# PIC32MK1024MCF064 device description
Architecture: MIPS; Family: PIC32MK; Series: PIC32MK
Registers are 32-bit, read-write, no defined reset value unless marked. A register's access mark holds for its fields unless they carry their own. Offsets are from the block's base; [hi:lo] are bit positions; 'fields as' and 'values as' point back to an identical list; <NAME> marks a mode.

## QEI
Instances: QEI 0x1f82b200 in periph_pb2_std
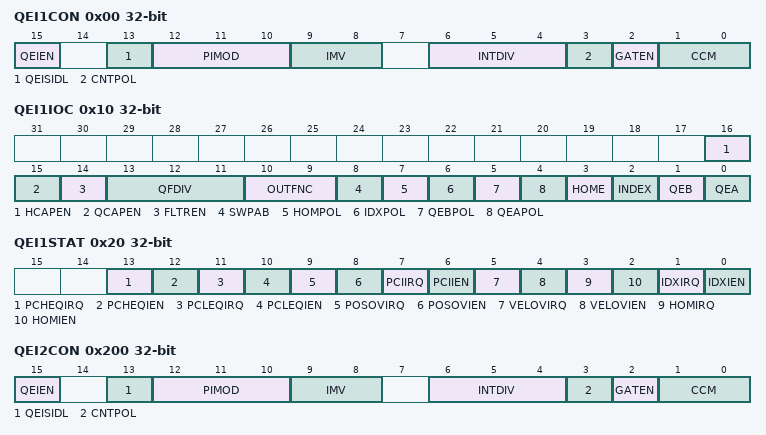
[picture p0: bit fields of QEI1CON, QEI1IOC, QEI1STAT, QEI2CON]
0x00 QEI1CON — QEIx Control Register
  [15] QEIEN — Quadrature Encoder Interface Module Counter Enable bit
    1=Module counters are enabled; 0=Module counters are disabled
  [13] QEISIDL — Stop in Idle Mode bit
    1=Discontinue module operation when device enters Idle mode; 0=Continue module operation in Idle mode
  [12:10] PIMOD — Position Counter Initialization Mode Select bits
    7=Modulo Count mode for position counter and every index event resets the position counter; 6=Modulo Count mode for position counter; 5=Resets the position counter when the position counter equals QEIxICCH register; 4=Second index event after home event initializes position counter with contents of QEIxICCHregister; 3=First index event after home event initializes position counter with contents of QEIxICCH register; 2=Next index input event initializes the position counter with contents of QEIxICCH register; 1=Every Index input event resets the position counter; 0=Index input event does not affect position counter
  [9:8] IMV — Index Match Value bits
    3=Index match occurs when QEB is 1 and QEA is 1; 2=Index match occurs when QEB is 1 and QEA is 0; 1=Index match occurs when QEB is 0 and QEA is 1; 0=Index match occurs when QEB is 0 and QEA is 0
  [6:4] INTDIV — Timer Input Clock Prescale Select bits
    7=1:128 prescale value; 6=1:64 prescale value; 5=1:32 prescale value; 4=1:16 prescale value; 3=1:8 prescale value; 2=1:4 prescale value; 1=1:2 prescale value; 0=1:1 prescale value
  [3] CNTPOL — Position and Index Counter/Timer Direction Select bit
    1=Counter direction is negative unless modified by external Up/Down signal; 0=Counter direction is positive unless modified by external Up/Down signal
  [2] GATEN — External Count Gate Enable bit
    1=External gate signal controls position counter operation; 0=External gate signal does not affect position counter/timer operation
  [1:0] CCM — Counter Control Mode Selection bits
    3=Internal Timer Mode. QEB High is Timer Run, QEB Low is Timer Stop; 2=QEA is the external clock input. QEB High is Clock Run, QEB Low is Clock Stop; 1=QEA is the external clock input. QEB High is Count Up, QEB Low is Count Down; 0=Quadrature Encoder Interface Count mode (x4 mode)
0x10 QEI1IOC — QEIx I/O Control Register
  [16] HCAPEN — Position Counter Input Capture by Home Event Enable bit
    1=HOMEx input event (positive edge) triggers a position capture event; 0=HOMEx input event (positive edge) does not trigger a position capture event
  [15] QCAPEN — Position Counter Input Capture Enable bit
    1=Positive edge detect of Home input triggers position capture function; 0=Home input event (positive edge) does not trigger a capture even
  [14] FLTREN — QEA/QEB/INDX/HOMEx Digital Filter Enable bit
    1=Input Pin Digital filter is enabled; 0=Input Pin Digital filter is disabled (bypassed)
  [13:11] QFDIV — QEA/QEB/INDX/HOMEx Digital Input Filter Clock Divide Select bits
    7=1:128 clock divide; 6=1:64 clock divide; 5=1:32 clock divide; 4=1:16 clock divide; 3=1:8 clock divide; 2=1:4 clock divide; 1=1:2 clock divide; 0=1:1 clock divide
  [10:9] OUTFNC — QEI Module Output Function Mode Select bits
    3=The CNTCMPx pin goes high when POSxCNT QEIxCMPL or POSxCNT QEIxICCH; 2=The CNTCMPx pin goes high when POSxCNT QEIxCMPL; 1=The CNTCMPx pin goes high when POSxCNT QEIxICCH; 0=Output is disabled
  [8] SWPAB — Swap QEA and QEB Inputs bit
    1=QEAx and QEBx are swapped prior to quadrature decoder logic; 0=QEAx and QEBx are not swapped
  [7] HOMPOL — HOMEx Input Polarity Select bit
    1=Input is inverted; 0=Input is not inverted
  [6] IDXPOL — INDXx Input Polarity Select bit
    1=Input is inverted; 0=Input is not inverted
  [5] QEBPOL — QEBx Input Polarity Select bit
    1=Input is inverted; 0=Input is not inverted
  [4] QEAPOL — QEAx Input Polarity Select bit
    1=Input is inverted; 0=Input is not inverted
  [3] HOME — Status of HOMEx Input Pin after Polarity Control bit
    1=(if HOMPOL bit is set to 0) Pin is at logic 1 / (if HOMPOL bit is set to 1) Pin is at logic 0; 0=(if HOMPOL bit is set to 0) Pin is at logic 0 / (if HOMPOL bit is set to 1) Pin is at logic 1
  [2] INDEX — Status of INDXx Input Pin after Polarity Control bit
    1=(if IDXPOL bit is set to 0) Pin is at logic 1 / (if IDXPOL bit is set to 1) Pin is at logic 0; 0=(if IDXPOL bit is set to 0) Pin is at logic 0 / (if IDXPOL bit is set to 1) Pin is at logic 1
  [1] QEB — Status of QEBx Input Pin after Polarity Control and SWPAB Pin Swapping bit
    1=see datasheet; 0=see datasheet
  [0] QEA — Status of QEAx Input Pin after Polarity Control and SWPAB Pin Swapping bit
    1=see datasheet; 0=see datasheet
0x20 QEI1STAT — QEIx Status Register
  [13] PCHEQIRQ — Position Counter Greater Than or Equal Compare Status bit
    1=POSxCNT; 0=POSxCNT < QEIxICCH
  [12] PCHEQIEN — Position Counter Greater Than or Equal Compare Interrupt Enable bit
    1=Interrupt is enabled; 0=Interrupt is disabled
  [11] PCLEQIRQ — Position Counter Less Than or Equal Compare Status bit
    1=POSxCNT; 0=POSxCNT > QEIxCMPL
  [10] PCLEQIEN — Position Counter Less Than or Equal Compare Interrupt Enable bit
    1=Interrupt is enabled; 0=Interrupt is disabled
  [9] POSOVIRQ — Position Counter Overflow Status bit
    1=Overflow has occurred; 0=No overflow has occurred
  [8] POSOVIEN — Position Counter Overflow Interrupt Enable bit
    1=Interrupt is enabled; 0=Interrupt is disabled
  [7] PCIIRQ — Position Counter Initialization Process Complete Status bit
    1=POSxCNT was reinitialized; 0=POSxCNT was not reinitialized
  [6] PCIIEN — Position Counter Initialization Process Complete Interrupt Enable bit
    1=Interrupt is enabled; 0=Interrupt is disabled
  [5] VELOVIRQ — Velocity Counter Overflow Status bit
    1=Overflow has occurred; 0=No overflow has not occurred
  [4] VELOVIEN — Velocity Counter Overflow Interrupt Enable bit
    1=Interrupt is enabled; 0=Interrupt is disabled
  [3] HOMIRQ — Status Flag for Home Event Status bit
    1=Home event has occurred; 0=No Home event has occurred
  [2] HOMIEN — Home Input Event Interrupt Enable bit
    1=Interrupt is enabled; 0=Interrupt is disabled
  [1] IDXIRQ — Status Flag for Index Event Status bit
    1=Index event has occurred; 0=No Index event has occurred
  [0] IDXIEN — Index Input Event Interrupt Enable bit
    1=Interrupt is enabled; 0=Interrupt is disabled
0x30 POS1CNT — Position Counter Register
  [31:0] POSCNT
0x40 POS1HLD
  [31:0] POSHLD
0x50 VEL1CNT — Velocity Counter Register
  [31:0] VELCNT
0x60 VEL1HLD — Velocity Hold Register
  [31:0] VELHLD
0x70 INT1TMR — Interval Timer Register
  [31:0] INTTMR
0x80 INT1HLD — Interval Timer Hold Register
  [31:0] INTHLD
0x90 INDX1CNT
  [31:0] INDXCNT
0xA0 INDX1HLD
  [31:0] INDXHLD
0xB0 QEI1ICC — QEIx Initialize/Capture/Compare Register
  [31:0] QEIICC
0xC0 QEI1CMPL — Capture Low Register
  [31:0] QEICMPL
0x200 QEI2CON — QEIx Control Register
  fields as QEI1CON
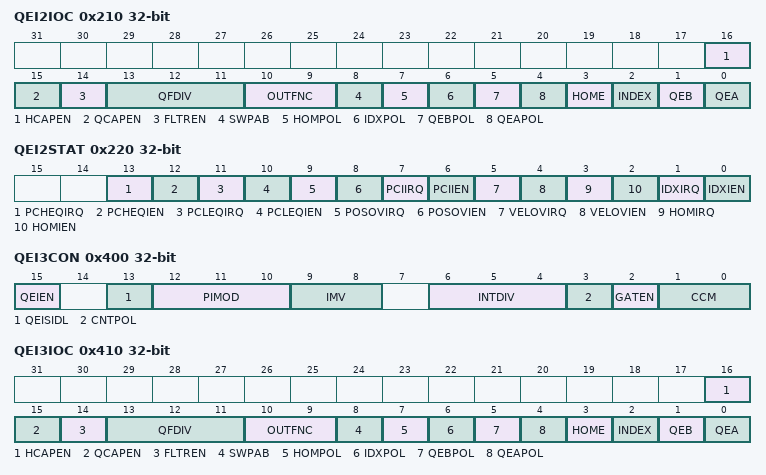
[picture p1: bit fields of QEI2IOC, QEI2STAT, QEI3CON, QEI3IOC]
0x210 QEI2IOC — QEIx I/O Control Register
  fields as QEI1IOC
0x220 QEI2STAT — QEIx Status Register
  fields as QEI1STAT
0x230 POS2CNT — Position Counter Register
  [31:0] POSCNT
0x240 POS2HLD
  [31:0] POSHLD
0x250 VEL2CNT — Velocity Counter Register
  [31:0] VELCNT
0x260 VEL2HLD — Velocity Hold Register
  [31:0] VELHLD
0x270 INT2TMR — Interval Timer Register
  [31:0] INTTMR
0x280 INT2HLD — Interval Timer Hold Register
  [31:0] INTHLD
0x290 INDX2CNT
  [31:0] INDXCNT
0x2A0 INDX2HLD
  [31:0] INDXHLD
0x2B0 QEI2ICC — QEIx Initialize/Capture/Compare Register
  [31:0] QEIICC
0x2C0 QEI2CMPL — Capture Low Register
  [31:0] QEICMPL
0x400 QEI3CON — QEIx Control Register
  fields as QEI1CON
0x410 QEI3IOC — QEIx I/O Control Register
  fields as QEI1IOC
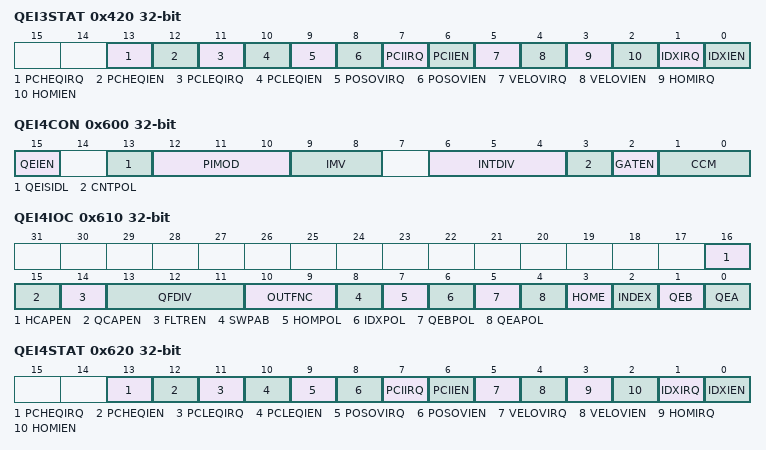
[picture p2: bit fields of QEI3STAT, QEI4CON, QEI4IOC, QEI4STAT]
0x420 QEI3STAT — QEIx Status Register
  fields as QEI1STAT
0x430 POS3CNT — Position Counter Register
  [31:0] POSCNT
0x440 POS3HLD
  [31:0] POSHLD
0x450 VEL3CNT — Velocity Counter Register
  [31:0] VELCNT
0x460 VEL3HLD — Velocity Hold Register
  [31:0] VELHLD
0x470 INT3TMR — Interval Timer Register
  [31:0] INTTMR
0x480 INT3HLD — Interval Timer Hold Register
  [31:0] INTHLD
0x490 INDX3CNT
  [31:0] INDXCNT
0x4A0 INDX3HLD
  [31:0] INDXHLD
0x4B0 QEI3ICC — QEIx Initialize/Capture/Compare Register
  [31:0] QEIICC
0x4C0 QEI3CMPL — Capture Low Register
  [31:0] QEICMPL
0x600 QEI4CON — QEIx Control Register
  fields as QEI1CON
0x610 QEI4IOC — QEIx I/O Control Register
  fields as QEI1IOC
0x620 QEI4STAT — QEIx Status Register
  fields as QEI1STAT
0x630 POS4CNT — Position Counter Register
  [31:0] POSCNT
0x640 POS4HLD
  [31:0] POSHLD
0x650 VEL4CNT — Velocity Counter Register
  [31:0] VELCNT
0x660 VEL4HLD — Velocity Hold Register
  [31:0] VELHLD
0x670 INT4TMR — Interval Timer Register
  [31:0] INTTMR
0x680 INT4HLD — Interval Timer Hold Register
  [31:0] INTHLD
0x690 INDX4CNT
  [31:0] INDXCNT
0x6A0 INDX4HLD
  [31:0] INDXHLD
0x6B0 QEI4ICC — QEIx Initialize/Capture/Compare Register
  [31:0] QEIICC
0x6C0 QEI4CMPL — Capture Low Register
  [31:0] QEICMPL
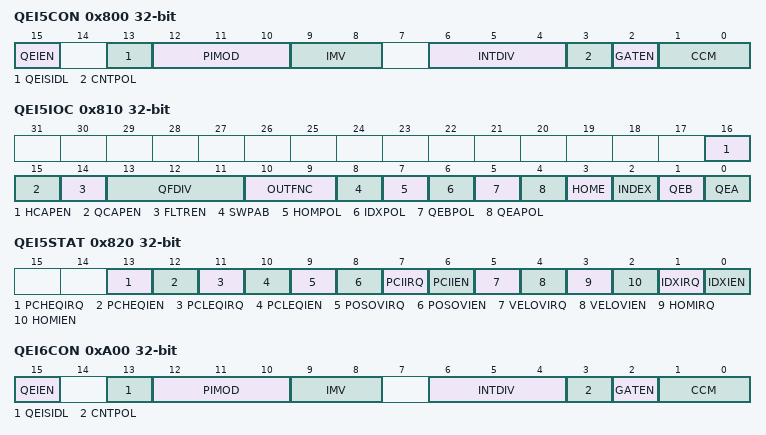
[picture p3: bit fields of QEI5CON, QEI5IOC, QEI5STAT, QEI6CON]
0x800 QEI5CON — QEIx Control Register
  fields as QEI1CON
0x810 QEI5IOC — QEIx I/O Control Register
  fields as QEI1IOC
0x820 QEI5STAT — QEIx Status Register
  fields as QEI1STAT
0x830 POS5CNT — Position Counter Register
  [31:0] POSCNT
0x840 POS5HLD
  [31:0] POSHLD
0x850 VEL5CNT — Velocity Counter Register
  [31:0] VELCNT
0x860 VEL5HLD — Velocity Hold Register
  [31:0] VELHLD
0x870 INT5TMR — Interval Timer Register
  [31:0] INTTMR
0x880 INT5HLD — Interval Timer Hold Register
  [31:0] INTHLD
0x890 INDX5CNT
  [31:0] INDXCNT
0x8A0 INDX5HLD
  [31:0] INDXHLD
0x8B0 QEI5ICC — QEIx Initialize/Capture/Compare Register
  [31:0] QEIICC
0x8C0 QEI5CMPL — Capture Low Register
  [31:0] QEICMPL
0xA00 QEI6CON — QEIx Control Register
  fields as QEI1CON
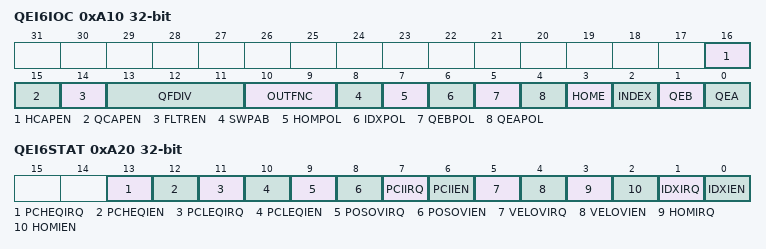
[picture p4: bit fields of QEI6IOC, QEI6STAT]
0xA10 QEI6IOC — QEIx I/O Control Register
  fields as QEI1IOC
0xA20 QEI6STAT — QEIx Status Register
  fields as QEI1STAT
0xA30 POS6CNT — Position Counter Register
  [31:0] POSCNT
0xA40 POS6HLD
  [31:0] POSHLD
0xA50 VEL6CNT — Velocity Counter Register
  [31:0] VELCNT
0xA60 VEL6HLD — Velocity Hold Register
  [31:0] VELHLD
0xA70 INT6TMR — Interval Timer Register
  [31:0] INTTMR
0xA80 INT6HLD — Interval Timer Hold Register
  [31:0] INTHLD
0xA90 INDX6CNT
  [31:0] INDXCNT
0xAA0 INDX6HLD
  [31:0] INDXHLD
0xAB0 QEI6ICC — QEIx Initialize/Capture/Compare Register
  [31:0] QEIICC
0xAC0 QEI6CMPL — Capture Low Register
  [31:0] QEICMPL
